# ATBTLC1000WLCSP register map
Vendor: Atmel Corp; Series: SAMB11; File version: TODO
CPU: CM0 r0p0, little endian, no MPU, no FPU, 2 interrupt priority bits
Address unit: 32 bits
Registers are 32-bit, read-write, reset 0x0 unless marked. A register's access mark holds for its fields unless they carry their own. Offsets are from the block's base; [hi:lo] are bit positions; {n}, {i} and the like mark numbered series; 'fields as' and 'values as' point back to an identical list.

## AON_GP_REGS0 — Always On General Purpose Registers
Base 0x4000F000
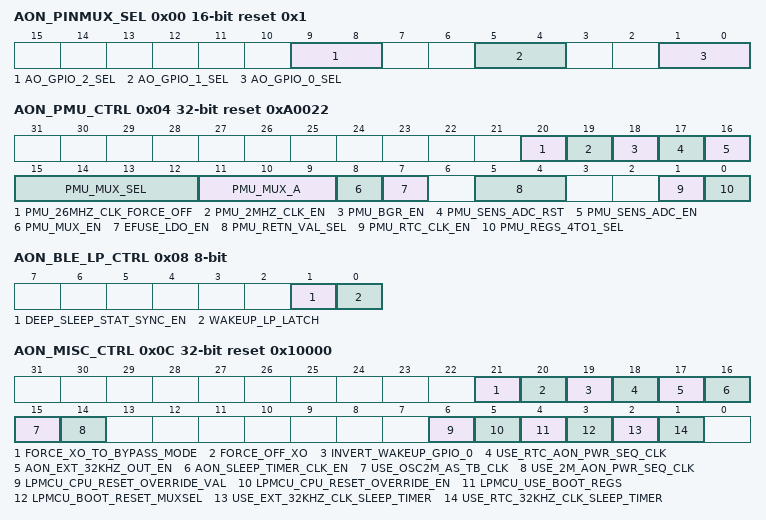
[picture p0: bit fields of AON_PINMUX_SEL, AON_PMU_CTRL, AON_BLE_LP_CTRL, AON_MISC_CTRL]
0x00 AON_PINMUX_SEL 16-bit reset 0x1 — Controls the pinmux selection for the AO GPIOs
  [9:8] AO_GPIO_2_SEL — Pinmux select for AO_GPIO_2
  [5:4] AO_GPIO_1_SEL — Pinmux select for AO_GPIO_1
  [1:0] AO_GPIO_0_SEL — Pinmux select for AO_GPIO_0
0x04 AON_PMU_CTRL reset 0xA0022 — Always On Misc Control
  [20] PMU_26MHZ_CLK_FORCE_OFF — If set, this will force off the OSC 26 MHz clock, otherwise this will follow the power for PD1
  [19] PMU_2MHZ_CLK_EN — Enables the 2MHz OSC clock coming to the digital from the PMU
  [18] PMU_BGR_EN
  [17] PMU_SENS_ADC_RST — PMU Sensor ADC Reset
  [16] PMU_SENS_ADC_EN — PMU Sensor ADC Enable
  [15:12] PMU_MUX_SEL
  [11:9] PMU_MUX_A
  [8] PMU_MUX_EN
  [7] EFUSE_LDO_EN — Enables the EFUSE LDO
  [5:4] PMU_RETN_VAL_SEL — Retention Voltage Selection
  [1] PMU_RTC_CLK_EN — Enables the PMU RTC clock
  [0] PMU_REGS_4TO1_SEL — If 1 then uses the frequency hopping table otherwise registers in PD0
0x08 AON_BLE_LP_CTRL 8-bit — Always On BLE LP Control
  [1] DEEP_SLEEP_STAT_SYNC_EN — If set, this will use the sync flops for deep sleep stat
  [0] WAKEUP_LP_LATCH — If set, this will latch the wakeup signal in the BLE LP block
0x0C AON_MISC_CTRL reset 0x10000 — Always On Misc Control
  [21] FORCE_XO_TO_BYPASS_MODE — If set, this will force the XO into bypass mode.
  [20] FORCE_OFF_XO — If set, this will force off the XO, otherwise XO is always on if BLE core is powered on.
  [19] INVERT_WAKEUP_GPIO_0 — If set, this will invert the wakeup gpio_0
  [18] USE_RTC_AON_PWR_SEQ_CLK — If set, this will use the RTC clock as the AON power sequencer clock once use_2m_aon_pwr_seq_clk is also set. This must be set first.
  [17] AON_EXT_32KHZ_OUT_EN — If set, this will enable the 32khz clock to the AON pads as an output of the chip
  [16] AON_SLEEP_TIMER_CLK_EN — If set, this will enable the 32khz clock to the AON Sleep Timer
  [15] USE_OSC2M_AS_TB_CLK — If set, this will use the osc 2M clock as the PD0 testbus clock
  [14] USE_2M_AON_PWR_SEQ_CLK — If set, this will use either the osc 2M or rtc 32kHz clock for the AON power sequencer. The field use_rtc_aon_pwr_seq_clk determines which.
  [6] LPMCU_CPU_RESET_OVERRIDE_VAL — If lpmcu_cpu_reset_override_en is set then this value will be used for the LPMCU CPU RESET
  [5] LPMCU_CPU_RESET_OVERRIDE_EN — If 1, then it will use the PD0 register value for LPMCU CPU RESET (higher priority than lpmcu_boot_reset_muxsel)
  [4] LPMCU_USE_BOOT_REGS — If 1, then the ARM will use the boot regs instead of the boot rom for the first 4 boot addresses (0x0 - 0xF)
  [3] LPMCU_BOOT_RESET_MUXSEL — If 1, then it uses the CPU register bit, otherwise LP_BOOT_PIN is connected
  [2] USE_EXT_32KHZ_CLK_SLEEP_TIMER — If set, this will use an external RTC for the 32khz clock for the sleep timer
  [1] USE_RTC_32KHZ_CLK_SLEEP_TIMER — If set, this will use the RTC version of the 32khz clock for the sleep timer
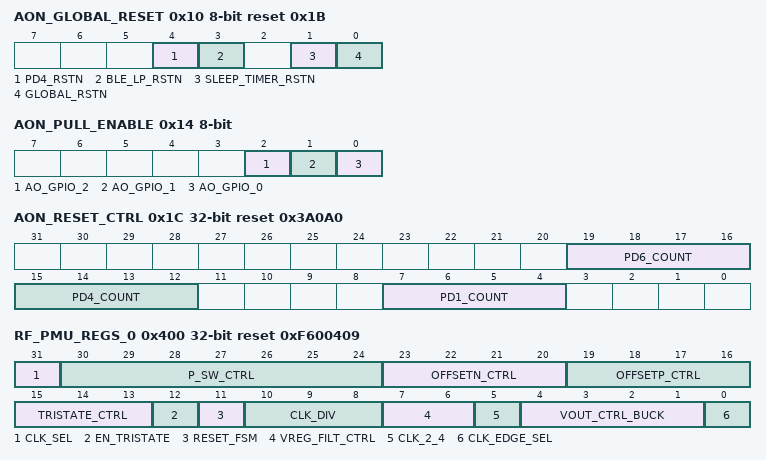
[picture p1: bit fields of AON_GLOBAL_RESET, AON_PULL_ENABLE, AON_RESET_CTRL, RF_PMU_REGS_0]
0x10 AON_GLOBAL_RESET 8-bit reset 0x1B — Active Low Always On Reset Control
  [4] PD4_RSTN — Allow the SW to force PD4 into reset
  [3] BLE_LP_RSTN — BLE Low Power Reset
  [1] SLEEP_TIMER_RSTN — Sleep Timer Reset
  [0] GLOBAL_RSTN — Global Reset
0x14 AON_PULL_ENABLE 8-bit — Active Low Always On Pull Enable Control
  [2] AO_GPIO_2 — Pull Enable for AO_GPIO_2
  [1] AO_GPIO_1 — Pull Enable for AO_GPIO_1
  [0] AO_GPIO_0 — Pull Enable for AO_GPIO_0
0x1C AON_RESET_CTRL reset 0x3A0A0 — Reset Count Control for PD1, PD4, PD6 and PD7
  [19:16] PD6_COUNT — Number of clock cycles to delay the PD6 reset
  [15:12] PD4_COUNT — Number of clock cycles to delay the PD4 reset. Upper 4 MSBs only (bits 3:0 will be forced to 0)
  [7:4] PD1_COUNT — Number of clock cycles to delay the PD1 reset. (also for PD7) Upper 4 MSBs only (bits 3:0 will be forced to 0)
0x20 AON_BTRIM_ACTIVE 8-bit reset 0x8 (reset mask 0xF) — BTRIM settings for active mode (i.e. not in retention)
0x24 AON_BTRIM_RETENTION 8-bit reset 0x8 (reset mask 0xF) — BTRIM settings for retention mode
0x40 AON_LPMCU_SCRATCH_PAD 8-bit — Usage for the LPMCU for any sort of status it needs to store for itself before it goes to sleep
0x44 AON_LPMCU_COLD_BOOT 8-bit reset 0x78 — To be used by ARM to determine if it is a cold boot or not
0x80 AON_BO_OUT_STATUS 8-bit ro (reset mask 0x1) — Brown Out Detected (must be cleared manually)
0x84 CLEAR_BROWN_OUT_REG 8-bit (reset mask 0x1) — Set to 1 to clear (hold until 0 read at aon_bo_out_status and then this must be cleared to detect another brown out condition)
0x400 RF_PMU_REGS_0 reset 0xF600409 — RF PMU Registers
  [31] CLK_SEL — Source clock for the buck converter
    0=Internal 26MHz clock; 1=External 52MHz clock
  [30:24] P_SW_CTRL — Power switch units for the buck converter
    0=0 power switches enabled; 1=1 power switch enabled; 3=2 power switches enabled; 7=3 power switches enabled; 15=4 power switches enabled; 31=5 power switches enabled; 63=6 power switches enabled
  [23:20] OFFSETN_CTRL — Controls a fixed comparator offset in the buck converter for negative pulses
    0=0.0mV offset; 1=0.4mV offset; 2=0.8mV offset; 3=1.2mV offset; 4=1.6mV offset; 5=2.0mV offset; 6=2.4mV offset; 7=2.8mV offset; 8=3.2mV offset; 9=3.6mV offset; 10=4.0mV offset; 11=4.4mV offset; 12=4.8mV offset; 13=5.2mV offset; 14=5.6mV offset; 15=6.0mV offset
  [19:16] OFFSETP_CTRL — Controls a fixed comparator offset in the buck converter for positive pulses
    values as OFFSETN_CTRL
  [15:13] TRISTATE_CTRL — Controls the minimum time between pulses in the buck converter
    0=Divide by 4; 1=Divide by 6; 2=Divide by 8; 3=Divide by 10; 4=Divide by 12; 5=Divide by 14; 6=Divide by 16
  [12] EN_TRISTATE — Allow tristate_ctrl to control minimum time between pulses of the buck converter
    0=Tristate logic disable; 1=Tristate logic enabled
  [11] RESET_FSM — Force reset of FSM in buck converter
    0=FSM is not reset; 1=FSM is reset
  [10:8] CLK_DIV — Programmable divider that sets the on duration of positive charging pulse
    values as TRISTATE_CTRL
  [7:6] VREG_FILT_CTRL — Not Used
  [5] CLK_2_4 — Comparator clock divider in buck converter
    0=Divide by 2; 1=Divide by 4
  [4:1] VOUT_CTRL_BUCK — Select the output voltage of the buck converter
    0=1.12V; 1=1.15V; 2=1.17V; 3=1.20V; 4=1.22V; 5=1.25V; 6=1.27V; 7=1.30V; 8=1.32V; 9=1.35V; 10=1.37V; 11=1.40V; 12=1.42V; 13=1.45V; 14=1.47V; 15=1.50V
  [0] CLK_EDGE_SEL — Select clock edge for Vreg comparator in buck converter
    0=Comparator samples on rising edge of clock; 1=Comparator samples on falling edge of clock
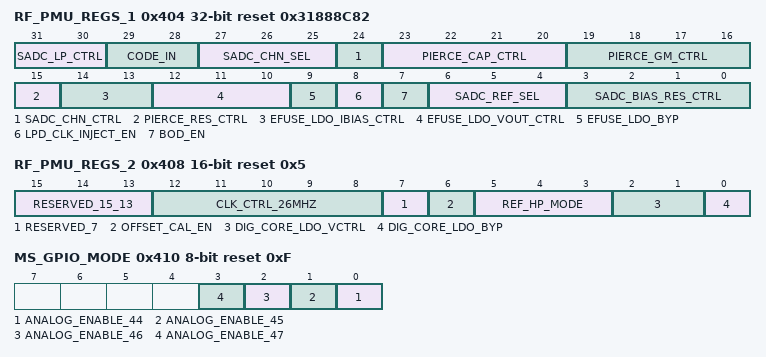
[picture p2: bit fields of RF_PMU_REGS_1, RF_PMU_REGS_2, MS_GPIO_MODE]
0x404 RF_PMU_REGS_1 reset 0x31888C82 — RF PMU Registers
  [31:30] SADC_LP_CTRL — Comparator biasing current for different sampling rates of the sensor ADC
    0=Comparator bias current is 4uA; 1=Comparator bias current is 8uA; 2=Comparator bias current is 20uA; 3=Comparator bias current is 24uA
  [29:28] CODE_IN — Optional mode to improve sub-ranging technique of the sensor ADC
    0=input dynamic range from 0V to VBATT voltage level; 1=input dynamic range from 0.08*VBATT to 0.92*VBATT; 2=input dynamic range from 0.17*VBATT to 0.83*VBATT; 3=input dynamic range from 0.25*VBATT to 0.75*VBATT
  [27:25] SADC_CHN_SEL — Input channel selection for the sensor ADC
    {v}=GPIO_MS{v+1} (v=0..3); 4=On Chip Temperature; 5=VBATT divided by 4 voltage level; 6=LP_LDO_OUT_1P2 low power domain voltage; 7=Sensor ADC reference voltage level
  [24] SADC_CHN_CTRL — enable input channel time multiplexing to the sensor ADC
    0=Conversion is done on the four input channels in a time multiplexed manner; 1=Conversion is done for one specific input channel
  [23:20] PIERCE_CAP_CTRL — On chip single ended capacitors for RTC oscillator
    {v}={v}pF (v=0..15)
  [19:16] PIERCE_GM_CTRL — Transconductance of RTC oscillator
    0=75nS; 1=85nS; 2=96nS; 3=106nS; 4=116nS; 5=127nS; 6=137nS; 7=147nS; 8=158nS; 9=168nS; 10=178nS; 11=189nS; 12=199nS; 13=209nS; 14=220nS; 15=230nS
  [15] PIERCE_RES_CTRL — RTC crystal circuit feedback resistance value
    0=20Mohm resistor; 1=30Mohm resistor
  [14:13] EFUSE_LDO_IBIAS_CTRL — Set the current bias for the EFUSE LDO
    0=80uA bias current; 1=100uA bias current; 2=120uA bias current; 3=140uA bias current
  [12:10] EFUSE_LDO_VOUT_CTRL — Output voltage of EFUSE LDO
    0=2.3V; 1=2.4V; 2=2.4V; 3=2.5V; 4=2.6V; 5=2.7V; 6=2.7V; 7=2.8V
  [9] EFUSE_LDO_BYP — Bypass controlf for EFUSE LDO
    0=EFUSE LDO regulates from VBATT voltage to 2.5V; 1=EFUSE LDO is bypass to VBATT voltage
  [8] LPD_CLK_INJECT_EN — Low Power Domain Clock Injection Enable Control
    0=Disable (Free running); 1=Enable (Lock to XO clock)
  [7] BOD_EN — Brown Out Detector Enable Control
    0=Disable; 1=Enable
  [6:4] SADC_REF_SEL — Reference Voltage Source for the Sensor ADC
    0=Buffered reference voltage; 1=IR voltage; 2=VBATT divided by 2; {v}=GPIO_MS{v-2} (v=3..6); 7=VBATT supply voltage
  [3:0] SADC_BIAS_RES_CTRL — Internal reference voltage level for sensor ADC
    0=0.5V; 1=0.6V; 2=0.7V; 3=0.8V; 4=0.9V; 5=1.0V; 6=1.1V (only for VBATT gt 2.0V); 7=1.2V (only for VBATT gt 2.0V); 8=1.3V (only for VBATT gt 2.0V); 9=1.4V (only for VBATT gt 2.0V); 10=1.5V (only for VBATT gt 2.0V); 11=1.6V (only for VBATT gt 2.0V); 12=1.7V (only for VBATT gt 2.0V); 13=1.8V (only for VBATT gt 2.0V); 14=1.9V (only for VBATT gt 2.0V); 15=2.0V (only for VBATT gt 2.0V)
0x408 RF_PMU_REGS_2 16-bit reset 0x5 — RF PMU Registers
  [15:13] RESERVED_15_13 — not using
  [12:8] CLK_CTRL_26MHZ — Control the 26MHz RC oscillator frequency
    {v}={v+12}MHz (v=0..31)
  [7] RESERVED_7 — not using
  [6] OFFSET_CAL_EN — Enable sensor ADC offset calibration
    0=Disable; 1=Enable
  [5:3] REF_HP_MODE — Controls the sensor ADCs internal reference buffer output resistance
    0=setting for applications that require less than 10KSPS; 1=setting for throughputs between 10KSPS and 100KSPS; 2=setting for 100KSPS; 3=setting for 325KSPS; 4=setting for 550KSPS; 5=setting for 775KSPS; 6=setting for 1MSPS
  [2:1] DIG_CORE_LDO_VCTRL — Voltage level of the digital core LDO when LDO is not in bypass mode
    0=0.91V; 1=0.96V; 2=1.02V; 3=1.09V
  [0] DIG_CORE_LDO_BYP — Bypass mode of digital core LDO which regulates from the buck converter output to the local power domains of each digital power island
    0=Not in bypass mode; 1=Bypass mode so output will be shorted to the buck converter output
0x410 MS_GPIO_MODE 8-bit reset 0xF — Analog Mode Select of Mixed Signal GPIOs
  [n-44] ANALOG_ENABLE_{n} (n=44..47) — Active High Analog Mode Enable for Mixed Signal LP_GPIO_{n}
0x414 IO_PADS_CONTROL 8-bit reset 0x1 — Controls behaviour of IO Pads in Sleep Mode
  [0] LATCH_ENABLE — Active High Latch Enable of IO Pads configuration parameters. When Low, Pads retain their configured state during sleep mode.
